VERSION ""

NS_ :

BS_:

BU_:

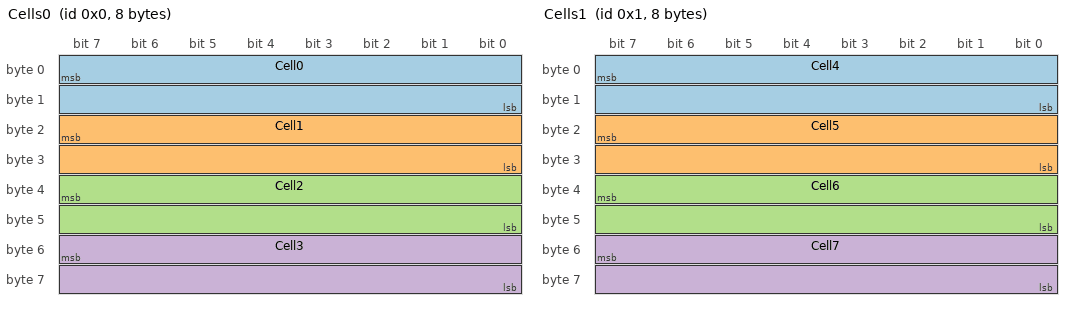
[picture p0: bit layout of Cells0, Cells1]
BO_ 0 Cells0: 8 Vector__XXX
 SG_ Cell0 : 7|16@0+ (1,0) [0|0] "V" Vector__XXX
 SG_ Cell1 : 23|16@0+ (1,0) [0|0] "V" Vector__XXX
 SG_ Cell2 : 39|16@0+ (1,0) [0|0] "V" Vector__XXX
 SG_ Cell3 : 55|16@0+ (1,0) [0|0] "V" Vector__XXX

BO_ 1 Cells1: 8 Vector__XXX
 SG_ Cell4 : 7|16@0+ (1,0) [0|0] "V" Vector__XXX
 SG_ Cell5 : 23|16@0+ (1,0) [0|0] "V" Vector__XXX
 SG_ Cell6 : 39|16@0+ (1,0) [0|0] "V" Vector__XXX
 SG_ Cell7 : 55|16@0+ (1,0) [0|0] "V" Vector__XXX

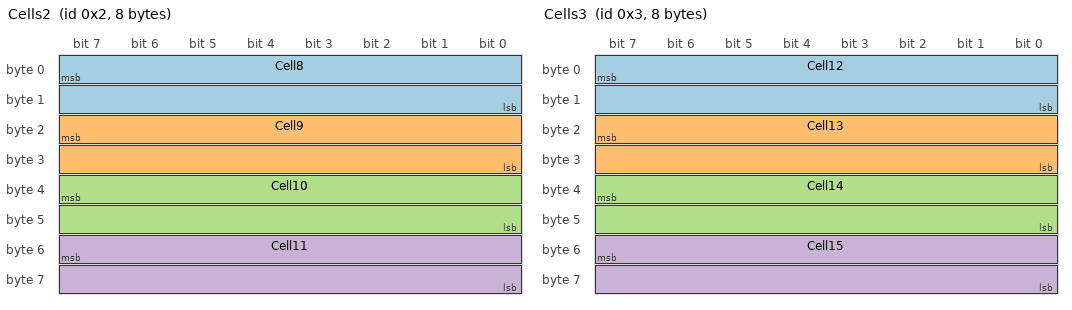
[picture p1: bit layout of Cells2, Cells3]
BO_ 2 Cells2: 8 Vector__XXX
 SG_ Cell8 : 7|16@0+ (1,0) [0|0] "V" Vector__XXX
 SG_ Cell9 : 23|16@0+ (1,0) [0|0] "V" Vector__XXX
 SG_ Cell10 : 39|16@0+ (1,0) [0|0] "V" Vector__XXX
 SG_ Cell11 : 55|16@0+ (1,0) [0|0] "V" Vector__XXX

BO_ 3 Cells3: 8 Vector__XXX
 SG_ Cell12 : 7|16@0+ (1,0) [0|0] "V" Vector__XXX
 SG_ Cell13 : 23|16@0+ (1,0) [0|0] "V" Vector__XXX
 SG_ Cell14 : 39|16@0+ (1,0) [0|0] "V" Vector__XXX
 SG_ Cell15 : 55|16@0+ (1,0) [0|0] "V" Vector__XXX

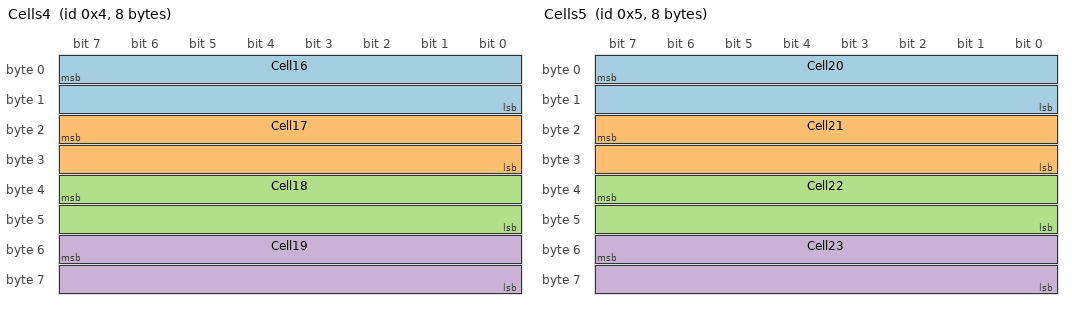
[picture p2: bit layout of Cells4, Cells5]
BO_ 4 Cells4: 8 Vector__XXX
 SG_ Cell16 : 7|16@0+ (1,0) [0|0] "V" Vector__XXX
 SG_ Cell17 : 23|16@0+ (1,0) [0|0] "V" Vector__XXX
 SG_ Cell18 : 39|16@0+ (1,0) [0|0] "V" Vector__XXX
 SG_ Cell19 : 55|16@0+ (1,0) [0|0] "V" Vector__XXX

BO_ 5 Cells5: 8 Vector__XXX
 SG_ Cell20 : 7|16@0+ (1,0) [0|0] "V" Vector__XXX
 SG_ Cell21 : 23|16@0+ (1,0) [0|0] "V" Vector__XXX
 SG_ Cell22 : 39|16@0+ (1,0) [0|0] "V" Vector__XXX
 SG_ Cell23 : 55|16@0+ (1,0) [0|0] "V" Vector__XXX

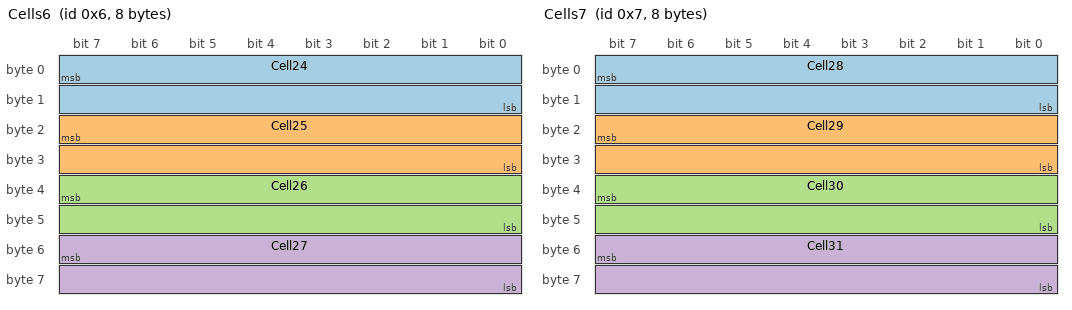
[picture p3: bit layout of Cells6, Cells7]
BO_ 6 Cells6: 8 Vector__XXX
 SG_ Cell24 : 7|16@0+ (1,0) [0|0] "V" Vector__XXX
 SG_ Cell25 : 23|16@0+ (1,0) [0|0] "V" Vector__XXX
 SG_ Cell26 : 39|16@0+ (1,0) [0|0] "V" Vector__XXX
 SG_ Cell27 : 55|16@0+ (1,0) [0|0] "V" Vector__XXX

BO_ 7 Cells7: 8 Vector__XXX
 SG_ Cell28 : 7|16@0+ (1,0) [0|0] "V" Vector__XXX
 SG_ Cell29 : 23|16@0+ (1,0) [0|0] "V" Vector__XXX
 SG_ Cell30 : 39|16@0+ (1,0) [0|0] "V" Vector__XXX
 SG_ Cell31 : 55|16@0+ (1,0) [0|0] "V" Vector__XXX

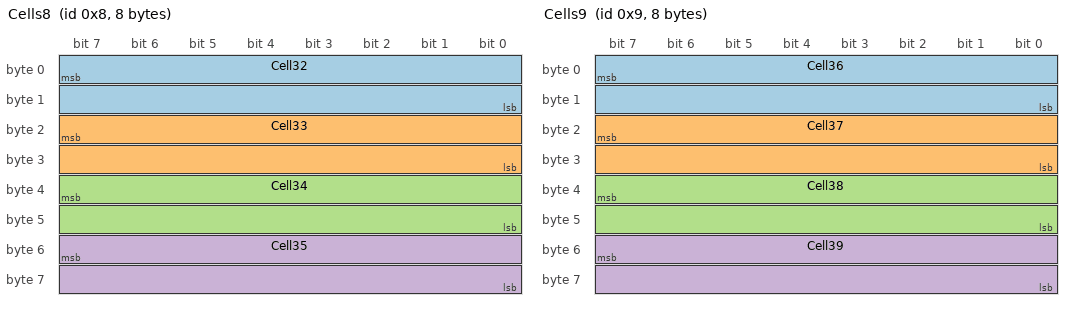
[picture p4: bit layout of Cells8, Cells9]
BO_ 8 Cells8: 8 Vector__XXX
 SG_ Cell32 : 7|16@0+ (1,0) [0|0] "V" Vector__XXX
 SG_ Cell33 : 23|16@0+ (1,0) [0|0] "V" Vector__XXX
 SG_ Cell34 : 39|16@0+ (1,0) [0|0] "V" Vector__XXX
 SG_ Cell35 : 55|16@0+ (1,0) [0|0] "V" Vector__XXX

BO_ 9 Cells9: 8 Vector__XXX
 SG_ Cell36 : 7|16@0+ (1,0) [0|0] "V" Vector__XXX
 SG_ Cell37 : 23|16@0+ (1,0) [0|0] "V" Vector__XXX
 SG_ Cell38 : 39|16@0+ (1,0) [0|0] "V" Vector__XXX
 SG_ Cell39 : 55|16@0+ (1,0) [0|0] "V" Vector__XXX

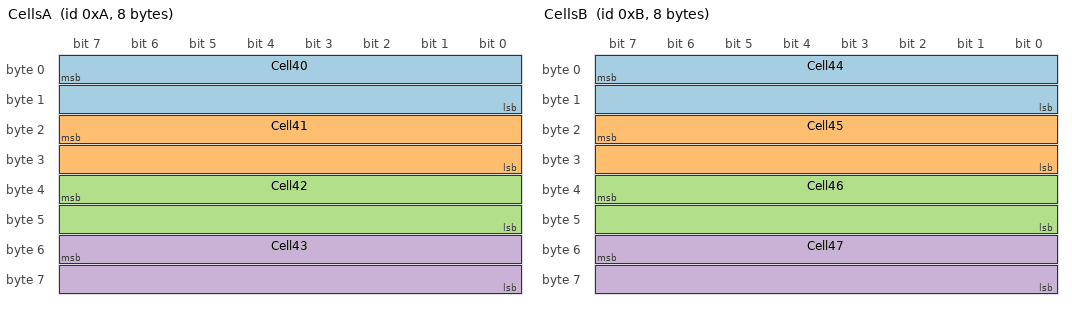
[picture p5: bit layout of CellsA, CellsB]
BO_ 10 CellsA: 8 Vector__XXX
 SG_ Cell40 : 7|16@0+ (1,0) [0|0] "V" Vector__XXX
 SG_ Cell41 : 23|16@0+ (1,0) [0|0] "V" Vector__XXX
 SG_ Cell42 : 39|16@0+ (1,0) [0|0] "V" Vector__XXX
 SG_ Cell43 : 55|16@0+ (1,0) [0|0] "V" Vector__XXX

BO_ 11 CellsB: 8 Vector__XXX
 SG_ Cell44 : 7|16@0+ (1,0) [0|0] "V" Vector__XXX
 SG_ Cell45 : 23|16@0+ (1,0) [0|0] "V" Vector__XXX
 SG_ Cell46 : 39|16@0+ (1,0) [0|0] "V" Vector__XXX
 SG_ Cell47 : 55|16@0+ (1,0) [0|0] "V" Vector__XXX

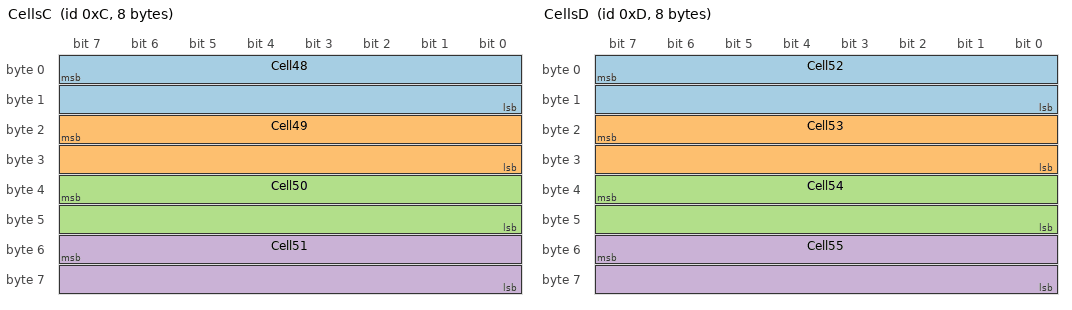
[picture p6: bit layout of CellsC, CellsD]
BO_ 12 CellsC: 8 Vector__XXX
 SG_ Cell48 : 7|16@0+ (1,0) [0|0] "V" Vector__XXX
 SG_ Cell49 : 23|16@0+ (1,0) [0|0] "V" Vector__XXX
 SG_ Cell50 : 39|16@0+ (1,0) [0|0] "V" Vector__XXX
 SG_ Cell51 : 55|16@0+ (1,0) [0|0] "V" Vector__XXX

BO_ 13 CellsD: 8 Vector__XXX
 SG_ Cell52 : 7|16@0+ (1,0) [0|0] "V" Vector__XXX
 SG_ Cell53 : 23|16@0+ (1,0) [0|0] "V" Vector__XXX
 SG_ Cell54 : 39|16@0+ (1,0) [0|0] "V" Vector__XXX
 SG_ Cell55 : 55|16@0+ (1,0) [0|0] "V" Vector__XXX

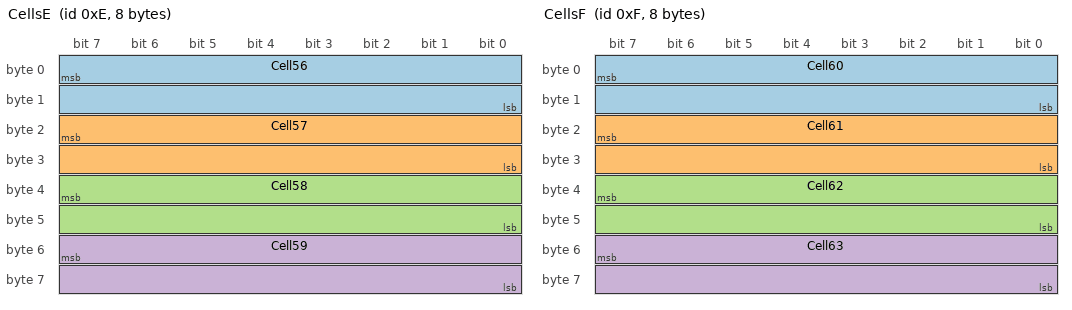
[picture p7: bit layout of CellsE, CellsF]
BO_ 14 CellsE: 8 Vector__XXX
 SG_ Cell56 : 7|16@0+ (1,0) [0|0] "V" Vector__XXX
 SG_ Cell57 : 23|16@0+ (1,0) [0|0] "V" Vector__XXX
 SG_ Cell58 : 39|16@0+ (1,0) [0|0] "V" Vector__XXX
 SG_ Cell59 : 55|16@0+ (1,0) [0|0] "V" Vector__XXX

BO_ 15 CellsF: 8 Vector__XXX
 SG_ Cell60 : 7|16@0+ (1,0) [0|0] "V" Vector__XXX
 SG_ Cell61 : 23|16@0+ (1,0) [0|0] "V" Vector__XXX
 SG_ Cell62 : 39|16@0+ (1,0) [0|0] "V" Vector__XXX
 SG_ Cell63 : 55|16@0+ (1,0) [0|0] "V" Vector__XXX

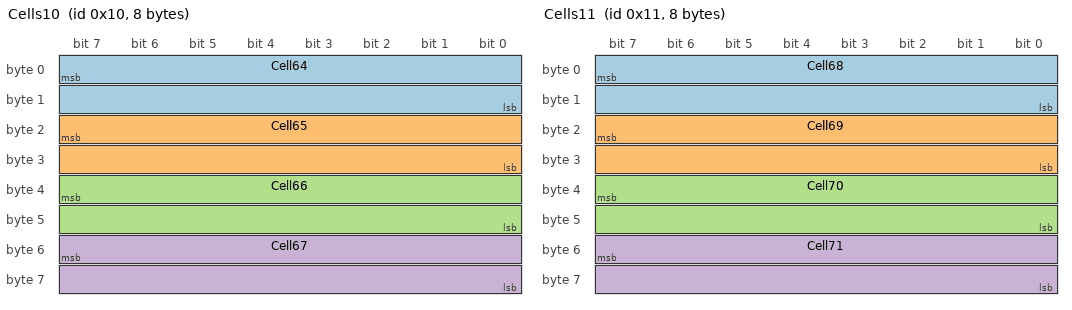
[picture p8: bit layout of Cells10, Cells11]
BO_ 16 Cells10: 8 Vector__XXX
 SG_ Cell64 : 7|16@0+ (1,0) [0|0] "V" Vector__XXX
 SG_ Cell65 : 23|16@0+ (1,0) [0|0] "V" Vector__XXX
 SG_ Cell66 : 39|16@0+ (1,0) [0|0] "V" Vector__XXX
 SG_ Cell67 : 55|16@0+ (1,0) [0|0] "V" Vector__XXX

BO_ 17 Cells11: 8 Vector__XXX
 SG_ Cell68 : 7|16@0+ (1,0) [0|0] "V" Vector__XXX
 SG_ Cell69 : 23|16@0+ (1,0) [0|0] "V" Vector__XXX
 SG_ Cell70 : 39|16@0+ (1,0) [0|0] "V" Vector__XXX
 SG_ Cell71 : 55|16@0+ (1,0) [0|0] "V" Vector__XXX

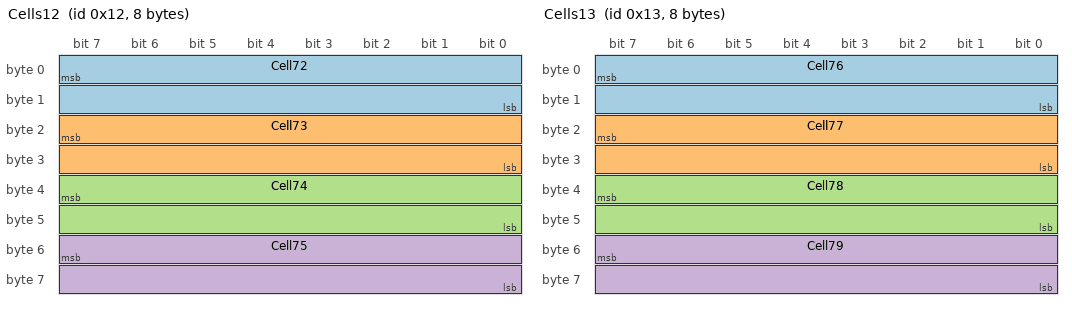
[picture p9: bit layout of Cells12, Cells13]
BO_ 18 Cells12: 8 Vector__XXX
 SG_ Cell72 : 7|16@0+ (1,0) [0|0] "V" Vector__XXX
 SG_ Cell73 : 23|16@0+ (1,0) [0|0] "V" Vector__XXX
 SG_ Cell74 : 39|16@0+ (1,0) [0|0] "V" Vector__XXX
 SG_ Cell75 : 55|16@0+ (1,0) [0|0] "V" Vector__XXX

BO_ 19 Cells13: 8 Vector__XXX
 SG_ Cell76 : 7|16@0+ (1,0) [0|0] "V" Vector__XXX
 SG_ Cell77 : 23|16@0+ (1,0) [0|0] "V" Vector__XXX
 SG_ Cell78 : 39|16@0+ (1,0) [0|0] "V" Vector__XXX
 SG_ Cell79 : 55|16@0+ (1,0) [0|0] "V" Vector__XXX

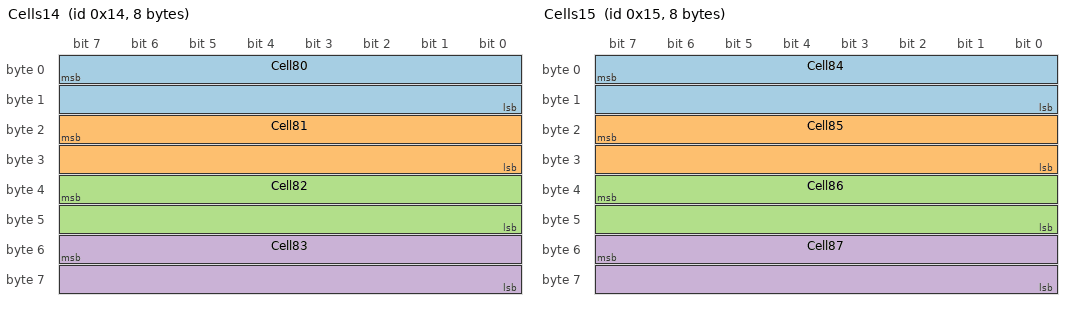
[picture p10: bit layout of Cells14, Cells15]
BO_ 20 Cells14: 8 Vector__XXX
 SG_ Cell80 : 7|16@0+ (1,0) [0|0] "V" Vector__XXX
 SG_ Cell81 : 23|16@0+ (1,0) [0|0] "V" Vector__XXX
 SG_ Cell82 : 39|16@0+ (1,0) [0|0] "V" Vector__XXX
 SG_ Cell83 : 55|16@0+ (1,0) [0|0] "V" Vector__XXX

BO_ 21 Cells15: 8 Vector__XXX
 SG_ Cell84 : 7|16@0+ (1,0) [0|0] "V" Vector__XXX
 SG_ Cell85 : 23|16@0+ (1,0) [0|0] "V" Vector__XXX
 SG_ Cell86 : 39|16@0+ (1,0) [0|0] "V" Vector__XXX
 SG_ Cell87 : 55|16@0+ (1,0) [0|0] "V" Vector__XXX

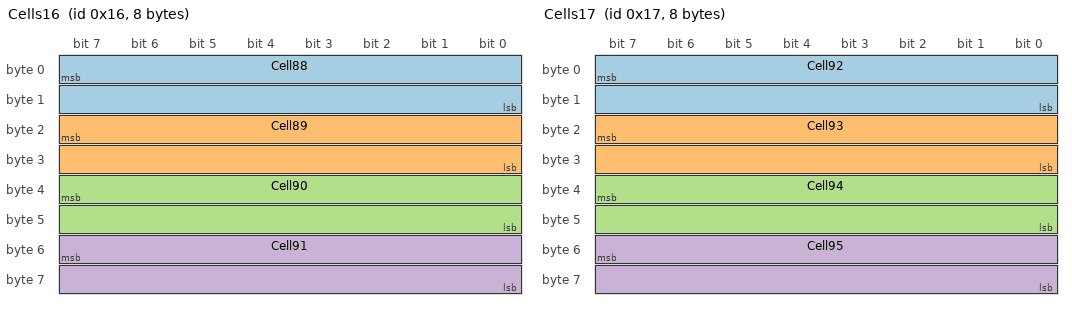
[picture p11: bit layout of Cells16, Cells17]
BO_ 22 Cells16: 8 Vector__XXX
 SG_ Cell88 : 7|16@0+ (1,0) [0|0] "V" Vector__XXX
 SG_ Cell89 : 23|16@0+ (1,0) [0|0] "V" Vector__XXX
 SG_ Cell90 : 39|16@0+ (1,0) [0|0] "V" Vector__XXX
 SG_ Cell91 : 55|16@0+ (1,0) [0|0] "V" Vector__XXX

BO_ 23 Cells17: 8 Vector__XXX
 SG_ Cell92 : 7|16@0+ (1,0) [0|0] "V" Vector__XXX
 SG_ Cell93 : 23|16@0+ (1,0) [0|0] "V" Vector__XXX
 SG_ Cell94 : 39|16@0+ (1,0) [0|0] "V" Vector__XXX
 SG_ Cell95 : 55|16@0+ (1,0) [0|0] "V" Vector__XXX

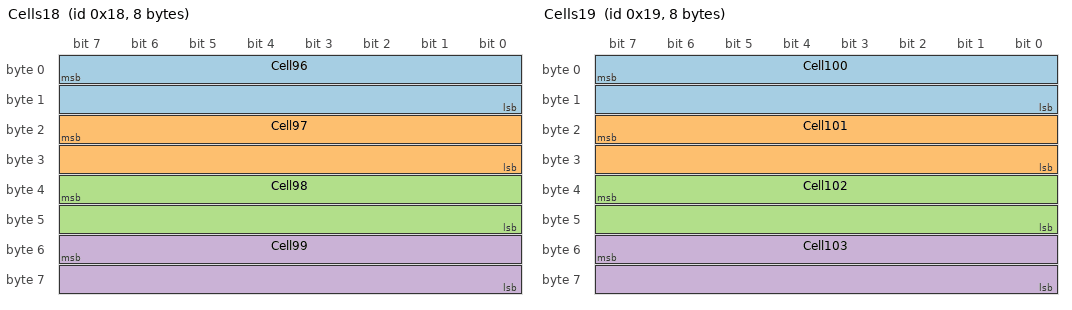
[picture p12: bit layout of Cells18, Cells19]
BO_ 24 Cells18: 8 Vector__XXX
 SG_ Cell96 : 7|16@0+ (1,0) [0|0] "V" Vector__XXX
 SG_ Cell97 : 23|16@0+ (1,0) [0|0] "V" Vector__XXX
 SG_ Cell98 : 39|16@0+ (1,0) [0|0] "V" Vector__XXX
 SG_ Cell99 : 55|16@0+ (1,0) [0|0] "V" Vector__XXX

BO_ 25 Cells19: 8 Vector__XXX
 SG_ Cell100 : 7|16@0+ (1,0) [0|0] "V" Vector__XXX
 SG_ Cell101 : 23|16@0+ (1,0) [0|0] "V" Vector__XXX
 SG_ Cell102 : 39|16@0+ (1,0) [0|0] "V" Vector__XXX
 SG_ Cell103 : 55|16@0+ (1,0) [0|0] "V" Vector__XXX
